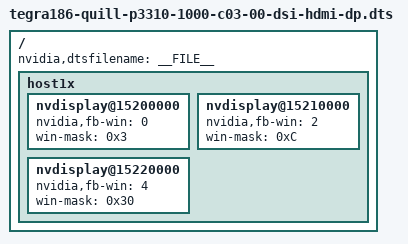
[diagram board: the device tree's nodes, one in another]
/*
 * tegra186-quill-p3310-1000-c03-00-base.dts: DTS file for Quill C03
 * boards to enable display on all three heads: DSI, HDMI and DP.
 * Assigned two windows per head, 2:2:2 window configuration.
 *
 * Copyright (c) 2016-2017, NVIDIA CORPORATION.  All rights reserved.
 *
 * This program is free software; you can redistribute it and/or modify
 * it under the terms of the GNU General Public License as published by
 * the Free Software Foundation; version 2 of the License.
 *
 * This program is distributed in the hope that it will be useful, but WITHOUT
 * ANY WARRANTY; without even the implied warranty of MERCHANTABILITY or
 * FITNESS FOR A PARTICULAR PURPOSE.  See the GNU General Public License for
 * more details.
 *
 */

#include "tegra186-quill-p3310-1000-c03-00-base.dts"

/ {
	nvidia,dtsfilename = __FILE__;

	host1x {
		nvdisplay@15200000 {
			nvidia,fb-win = <0>;
			win-mask = <0x3>;
		};

		nvdisplay@15210000 {
			nvidia,fb-win = <2>;
			win-mask = <0xC>;
		};

		nvdisplay@15220000 {
			nvidia,fb-win = <4>;
			win-mask = <0x30>;
		};
	};
};
